AUTOSAR XML (schema 4-3-0)
package /ComponentTypes
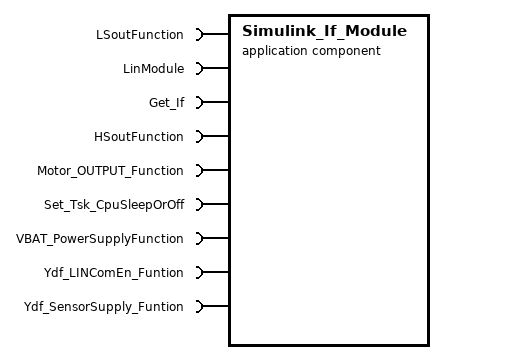
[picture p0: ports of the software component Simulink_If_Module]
  application sw component type Simulink_If_Module
    9 x require port:
      LSoutFunction: required-interface=LSoutFunction
        required-com-specs:
          Lowout{1..4}_Function
          Lowout20_Function
          Lowout{22..24}_Function
          Lowout_Lamp1_Function
          Lowout_Lamp2_Function
          Lowout_PWMOUT1_Function
          Lowout_PWMOUT2_Function
          Lowout{5..19}_Function
          Lowout21_Function
      LinModule: required-interface=LinModule
        required-com-specs:
          LinA_Master_Send
          LinB_Master_Send
          LinC_Master_Send
          LinA_Slave_Response
          LinB_Slave_Response
          LinC_Slave_Response
          LinARec_GetResult
          LinBRec_GetResult
          LinCRec_GetResult
          LinD_Master_Send
          LinD_Slave_Response
          LinDRec_GetResult
      Get_If: required-interface=Get_If
        required-com-specs:
          Get_Ad_Result
          Get_io_inResult
          Get_BTS_OutResult
          Get_CAN_ActiveInf
          Icu_17_GtmCcu6_PWMIN_CH{1..4}
          Icu_17_GtmCcu6_PWMIN_PWMSCB1
          Icu_17_GtmCcu6_PWMIN_PWMSCB2
          Icu_17_GtmCcu6_PWMIN_LAMPSCB1
          Icu_17_GtmCcu6_PWMIN_LAMPSCB2
          Get_Bottom_Ver
          Get_SentData
          Get_Level_OutResult
          Get_PwmOrLevel_OutResult
          Get_Motor_OutResult
      HSoutFunction: required-com-specs=[High_Side1_Function, High_Side2_Function, High_Side3_Function, High_Side4_Function], required-interface=HSoutFunction
      Motor_OUTPUT_Function: client-com-spec=App_Motor_OUTPUT_Function, required-interface=Motor_OUTPUT_Function
      Set_Tsk_CpuSleepOrOff: client-com-spec=Set_Tsk_CpuSleepOrOff, required-interface=Set_Tsk_CpuSleepOrOff
      VBAT_PowerSupplyFunction: required-com-specs=[D_VBAT_A_OFF, D_VBAT_B_OFF], required-interface=VBAT_PowerSupplyFunction
      Ydf_LINComEn_Funtion: required-com-specs=[LINB_OUT_Enable, LINC_OUT_Enable, LIND_OUT_Enable], required-interface=Ydf_LINComEn_Funtion
      Ydf_SensorSupply_Funtion: required-com-specs=[SensorSupply3_5v_OUT_Enable, SensorSupply4_5v_OUT_Enable], required-interface=Ydf_SensorSupply_Funtion
    behavior Simulink_If_Module_InternalBehavior
      5 x timing event, all with period=0.01:
        TMT_LinCom_Driver: start-on-event=LinCom_Driver
        TMT_GetInfo_Input: start-on-event=Input_Driver
        TMT_Output_Driver: start-on-event=Output_Driver
        TMT_PowerSupply_Driver: start-on-event=PowerSupply_Driver
        TMT_ApplicationSW: start-on-event=ApplicationSW
      5 x runnable:
        Input_Driver
          17 x sync call:
            SC_Get_If_Get_Ad_Result: operation=Get_If.Get_Ad_Result
            SC_Get_If_Get_BTS_OutResult: operation=Get_If.Get_BTS_OutResult
            SC_Get_If_Get_Bottom_Ver: operation=Get_If.Get_Bottom_Ver
            SC_Get_If_Get_CAN_ActiveInf: operation=Get_If.Get_CAN_ActiveInf
            SC_Get_If_Get_Level_OutResult: operation=Get_If.Get_Level_OutResult
            SC_Get_If_Get_Motor_OutResult: operation=Get_If.Get_Motor_OutResult
            SC_Get_If_Get_PwmOrLevel_OutResult: operation=Get_If.Get_PwmOrLevel_OutResult
            SC_Get_If_Get_SentData: operation=Get_If.Get_SentData
            SC_Get_If_Get_io_inResult: operation=Get_If.Get_io_inResult
            SC_Get_If_Icu_17_GtmCcu6_PWMIN_CH{1..4}: operation=Get_If.Icu_17_GtmCcu6_PWMIN_CH{1..4}
            SC_Get_If_Icu_17_GtmCcu6_PWMIN_LAMPSCB1: operation=Get_If.Icu_17_GtmCcu6_PWMIN_LAMPSCB1
            SC_Get_If_Icu_17_GtmCcu6_PWMIN_LAMPSCB2: operation=Get_If.Icu_17_GtmCcu6_PWMIN_LAMPSCB2
            SC_Get_If_Icu_17_GtmCcu6_PWMIN_PWMSCB1: operation=Get_If.Icu_17_GtmCcu6_PWMIN_PWMSCB1
            SC_Get_If_Icu_17_GtmCcu6_PWMIN_PWMSCB2: operation=Get_If.Icu_17_GtmCcu6_PWMIN_PWMSCB2
        Output_Driver
          33 x sync call:
            SC_HSoutFunction_High_Side{1..4}_Function: operation=HSoutFunction.High_Side{1..4}_Function
            SC_LSoutFunction_Lowout{10..19}_Function: operation=LSoutFunction.Lowout{10..19}_Function
            SC_LSoutFunction_Lowout1_Function: operation=LSoutFunction.Lowout1_Function
            SC_LSoutFunction_Lowout{20..24}_Function: operation=LSoutFunction.Lowout{20..24}_Function
            SC_LSoutFunction_Lowout{2..9}_Function: operation=LSoutFunction.Lowout{2..9}_Function
            SC_LSoutFunction_Lowout_Lamp1_Function: operation=LSoutFunction.Lowout_Lamp1_Function
            SC_LSoutFunction_Lowout_Lamp2_Function: operation=LSoutFunction.Lowout_Lamp2_Function
            SC_LSoutFunction_Lowout_PWMOUT1_Function: operation=LSoutFunction.Lowout_PWMOUT1_Function
            SC_LSoutFunction_Lowout_PWMOUT2_Function: operation=LSoutFunction.Lowout_PWMOUT2_Function
            SC_Motor_OUTPUT_Function_App_Motor_OUTPUT_Function: operation=Motor_OUTPUT_Function.App_Motor_OUTPUT_Function
        LinCom_Driver
          15 x sync call:
            SC_LinModule_LinARec_GetResult: operation=LinModule.LinARec_GetResult
            SC_LinModule_LinA_Master_Send: operation=LinModule.LinA_Master_Send
            SC_LinModule_LinA_Slave_Response: operation=LinModule.LinA_Slave_Response
            SC_LinModule_LinBRec_GetResult: operation=LinModule.LinBRec_GetResult
            SC_LinModule_LinB_Master_Send: operation=LinModule.LinB_Master_Send
            SC_LinModule_LinB_Slave_Response: operation=LinModule.LinB_Slave_Response
            SC_LinModule_LinCRec_GetResult: operation=LinModule.LinCRec_GetResult
            SC_LinModule_LinC_Master_Send: operation=LinModule.LinC_Master_Send
            SC_LinModule_LinC_Slave_Response: operation=LinModule.LinC_Slave_Response
            SC_LinModule_LinDRec_GetResult: operation=LinModule.LinDRec_GetResult
            SC_LinModule_LinD_Master_Send: operation=LinModule.LinD_Master_Send
            SC_LinModule_LinD_Slave_Response: operation=LinModule.LinD_Slave_Response
            SC_Ydf_LINComEn_Funtion_LINB_OUT_Enable: operation=Ydf_LINComEn_Funtion.LINB_OUT_Enable
            SC_Ydf_LINComEn_Funtion_LINC_OUT_Enable: operation=Ydf_LINComEn_Funtion.LINC_OUT_Enable
            SC_Ydf_LINComEn_Funtion_LIND_OUT_Enable: operation=Ydf_LINComEn_Funtion.LIND_OUT_Enable
        PowerSupply_Driver
          5 x sync call:
            SC_Set_Tsk_CpuSleepOrOff_Set_Tsk_CpuSleepOrOff: operation=Set_Tsk_CpuSleepOrOff.Set_Tsk_CpuSleepOrOff
            SC_VBAT_PowerSupplyFunction_D_VBAT_A_OFF: operation=VBAT_PowerSupplyFunction.D_VBAT_A_OFF
            SC_VBAT_PowerSupplyFunction_D_VBAT_B_OFF: operation=VBAT_PowerSupplyFunction.D_VBAT_B_OFF
            SC_Ydf_SensorSupply_Funtion_SensorSupply3_5v_OUT_Enable: operation=Ydf_SensorSupply_Funtion.SensorSupply3_5v_OUT_Enable
            SC_Ydf_SensorSupply_Funtion_SensorSupply4_5v_OUT_Enable: operation=Ydf_SensorSupply_Funtion.SensorSupply4_5v_OUT_Enable
        ApplicationSW
  swc implementation Simulink_If_Module_Implementation: behavior=Simulink_If_Module_InternalBehavior
